# PIC32CX1025MTSH128 register map
Vendor: Microchip Technology; Series: PIC32CXMTSH; File version: 0
CPU: CM4 r0p1, selectable endian, MPU, FPU, 4 interrupt priority bits
Registers are 32-bit, read-write, reset 0x0 unless marked. A register's access mark holds for its fields unless they carry their own. Offsets are from the block's base; [hi:lo] are bit positions; {n}, {i} and the like mark numbered series.

## SEFC0 — Secure Embedded Flash Controller
Base 0x460E0000; register names take the prefix SEFC_
Same registers: SEFC1 0x460E0200
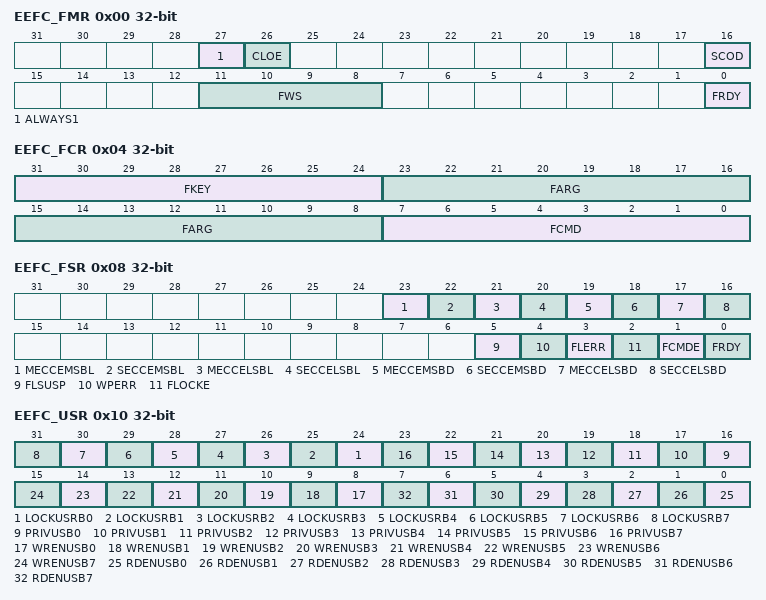
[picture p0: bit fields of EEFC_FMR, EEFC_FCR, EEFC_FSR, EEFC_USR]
0x00 EEFC_FMR — SEFC Flash Mode Register
  [27] ALWAYS1 — Always Written to One
  [26] CLOE — Code Loop Optimization Enable
  [16] SCOD — Sequential Code Optimization Disable
  [11:8] FWS — Flash Wait State
  [0] FRDY — Flash Ready Interrupt Enable
0x04 EEFC_FCR wo — SEFC Flash Command Register
  [31:24] FKEY — Flash Writing Protection Key
    90=PASSWD (The 0x5A value enables the command defined by the bits in the register. If the field is written with a different value, the write is not performed and no action is started.)
  [23:8] FARG — Flash Command Argument
  [7:0] FCMD — Flash Command
    0=GETD (Get Flash descriptor); 1=WP (Write page); 2=WPL (Write page and lock); 7=EPA (Erase pages (8, 16, 32, 64)); 8=SLB (Set lock bit); 9=CLB (Clear lock bit); 10=GLB (Get lock bit); 11=SGPB (Set GPNVM bit); 12=CGPB (Clear GPNVM bit); 13=GGPB (Get GPNVM bit); 14=STUI (Start read unique identifier); 15=SPUI (Stop read unique identifier); 16=GCALB (Get CALIB bit); 17=ES (Erase sector); 18=WUS (Write user signature); 19=EUS (Erase user signature); 20=STUS (Start read user signature); 21=SPUS (Stop read user signature); 23=SUSP (Suspend); 24=RES (Resume); 25=SCK (Send cryptographic key)
0x08 EEFC_FSR ro — SEFC Flash Status Register
  [23] MECCEMSBL — Multiple ECC Error on MSB Part of the Memory Lock Bits
  [22] SECCEMSBL — Single ECC Error on MSB Part of the Memory Lock Bits
  [21] MECCELSBL — Multiple ECC Error on LSB Part of the Memory Lock Bits
  [20] SECCELSBL — Single ECC Error on LSB Part of the Memory Lock Bits
  [19] MECCEMSBD — Multiple ECC Error on MSB Part of the Memory Flash Data Bus (cleared on read)
  [18] SECCEMSBD — Single ECC Error on MSB Part of the Memory Flash Data Bus (cleared on read)
  [17] MECCELSBD — Multiple ECC Error on LSB Part of the Memory Flash Data Bus (cleared on read)
  [16] SECCELSBD — Single ECC Error on LSB Part of the Memory Flash Data Bus (cleared on read)
  [5] FLSUSP — Flash Suspended Status (cleared when resuming the programming operation)
  [4] WPERR — Write Protection Error Status (cleared on read)
  [3] FLERR — Flash Error Status (cleared when a programming operation starts)
  [2] FLOCKE — Flash Lock Error Status (cleared on read or by writing EEFC_FCR)
  [1] FCMDE — Flash Command Error Status (cleared on read)
  [0] FRDY — Flash Ready Status (cleared when Flash is busy)
0x0C EEFC_FRR ro — SEFC Flash Result Register
  [31:0] FVALUE — Flash Result Value
0x10 EEFC_USR — SEFC User Signature Rights Register
  [n+24] LOCKUSRB{n} (n=0..7) — Lock User Signature Rights for User Signature Block {n}
  [n+16] PRIVUSB{n} (n=0..7) — Privileged Access for User Signature Block {n}
  [n+8] WRENUSB{n} (n=0..7) — Write Enable for User Signature Block {n}
  [n] RDENUSB{n} (n=0..7) — Read Enable for User Signature Block {n}
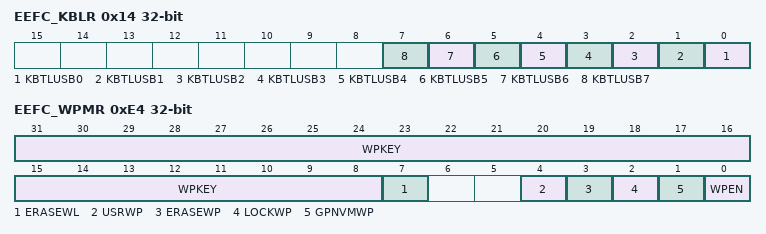
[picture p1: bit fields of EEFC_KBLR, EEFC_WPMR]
0x14 EEFC_KBLR — SEFC Key Bus Lock Register
  [n] KBTLUSB{n} (n=0..7) — Key Bus Transfer Lock from User Signature Block {n}
0xE4 EEFC_WPMR — Write Protection Mode Register
  [31:8] WPKEY — Write Protection Key
    0x454643=PASSWD (Writing any other value in this field aborts the write operation. Always reads as 0.)
  [7] ERASEWL — Erase and Write Lock
  [4] USRWP — User Signature Write Protection
  [3] ERASEWP — Erase and Write Protection
  [2] LOCKWP — Lock Bit Write Protection
  [1] GPNVMWP — GPNVM Bit Write Protection
  [0] WPEN — Write Protection Enable

## SFRBU — Special Function Register Backup
Base 0x40050600; register names take the prefix SFRBU_
0x10 XTAL_TRIM — XTAL Oscillator Trimming Register
  [1:0] XTAL_TRIM — 32 kHz Crystal Oscillator Trimming Value
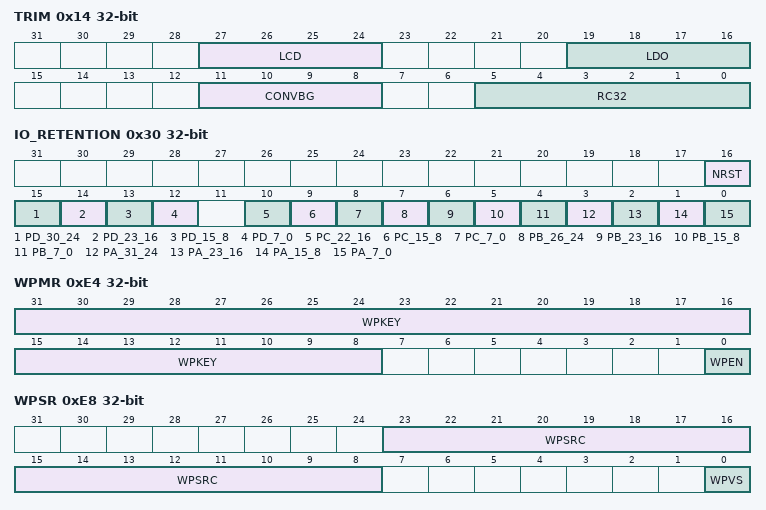
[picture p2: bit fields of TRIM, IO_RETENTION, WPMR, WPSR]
0x14 TRIM ro — Trimming Bits Register
  [27:24] LCD — LDO Internal Bandgap Trimming for LCD Driver
  [19:16] LDO — Power Management IP LDO Trimming Value
  [11:8] CONVBG — Conversion IP Bandgap Trimming Value
  [5:0] RC32 — RC Oscillator Trimming Value
0x20 BOOT
  [0] SOURCE — Source for Booting Sequence
0x30 IO_RETENTION
  [16] NRST — Keep Function on NRST
  [15] PD_30_24 — Keep Function on PD24 to PD30
  [14] PD_23_16 — Keep Function on PD16 to PD23
  [13] PD_15_8 — Keep Function on PD8 to PD15
  [12] PD_7_0 — Keep Function on PD0 to PD7
  [10] PC_22_16 — Keep Function on PC16 to PC22
  [9] PC_15_8 — Keep Function on PC8 to PC15
  [8] PC_7_0 — Keep Function on PC0 to PC7
  [7] PB_26_24 — Keep Function on PB24 to PB26
  [6] PB_23_16 — Keep Function on PB216 to PB23
  [5] PB_15_8 — Keep Function on PB8 to PB15
  [4] PB_7_0 — Keep Function on PB0 to PB7
  [3] PA_31_24 — Keep Function on PA24 to PA31
  [2] PA_23_16 — Keep Function on PA16 to PA23
  [1] PA_15_8 — Keep Function on PA8 to PA15
  [0] PA_7_0 — Keep Function on PA0 to PA7
0x40 BODCORE
  [0] STATUS — Core Brownout Detector
0x50 PWS_CNTRL — Power Switch Control Register
  [0] UNMASK — Unmask Power Switch Control Signals
0xE4 WPMR — Write Protection Mode Register
  [31:8] WPKEY — Write Protection Key
    0x534652=PASSWD (Writing any other value in this field aborts the write operation of the WPEN bit. Always reads as 0.)
  [0] WPEN — Write Protection Enable
0xE8 WPSR — Write Protection Status Register
  [23:8] WPSRC — Write Protection Source
  [0] WPVS — Write Protection Violation Status
0xF0 SPARE
  [31:0] VALUE — Spare
